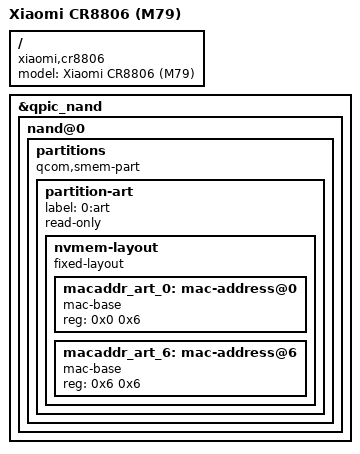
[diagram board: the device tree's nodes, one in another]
// SPDX-License-Identifier: GPL-2.0-or-later OR MIT

/dts-v1/;

#include "ipq5018-cr880x.dtsi"

/ {
	model = "Xiaomi CR8806 (M79)";
	compatible = "xiaomi,cr8806", "qcom,ipq5018";
};

&qpic_nand {
	nand@0 {
		partitions {
			compatible = "qcom,smem-part";

			partition-art {
				label = "0:art";
				read-only;

				nvmem-layout {
					compatible = "fixed-layout";
					#address-cells = <1>;
					#size-cells = <1>;

					macaddr_art_0: mac-address@0 {
						compatible = "mac-base";
						reg = <0x0 0x6>;
						#nvmem-cell-cells = <1>;
					};

					macaddr_art_6: mac-address@6 {
						compatible = "mac-base";
						reg = <0x6 0x6>;
						#nvmem-cell-cells = <1>;
					};
				};
			};
		};
	};
};
